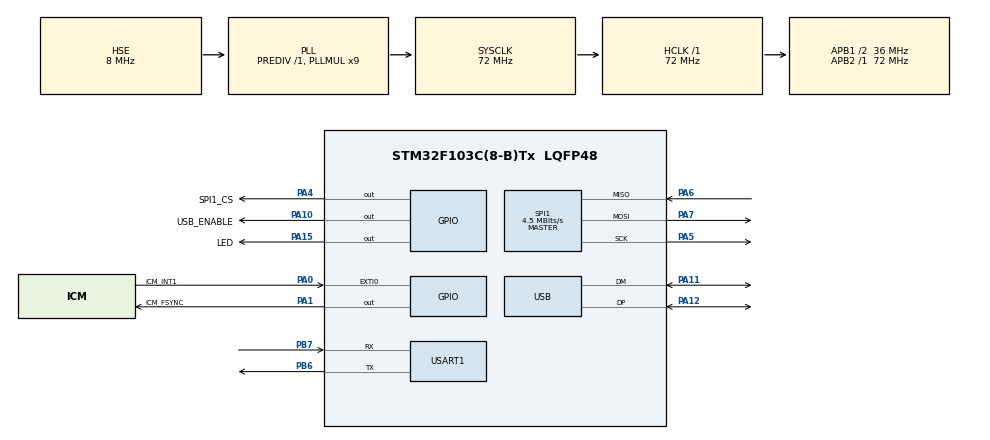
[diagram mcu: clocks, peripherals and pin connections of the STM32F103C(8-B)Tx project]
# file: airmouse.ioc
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Dma.Request0=SPI1_RX
Dma.Request1=SPI1_TX
Dma.Request2=USART1_RX
Dma.Request3=USART1_TX
Dma.SPI1_RX.0.Direction=DMA_PERIPH_TO_MEMORY
Dma.SPI1_RX.0.Instance=DMA1_Channel2
Dma.SPI1_RX.0.MemDataAlignment=DMA_MDATAALIGN_BYTE
Dma.SPI1_RX.0.MemInc=DMA_MINC_ENABLE
Dma.SPI1_RX.0.Mode=DMA_NORMAL
Dma.SPI1_RX.0.PeriphDataAlignment=DMA_PDATAALIGN_BYTE
Dma.SPI1_RX.0.PeriphInc=DMA_PINC_DISABLE
Dma.SPI1_RX.0.Priority=DMA_PRIORITY_LOW
Dma.SPI1_TX.1.Direction=DMA_MEMORY_TO_PERIPH
Dma.SPI1_TX.1.Instance=DMA1_Channel3
Dma.SPI1_TX.1.MemDataAlignment=DMA_MDATAALIGN_BYTE
Dma.SPI1_TX.1.MemInc=DMA_MINC_ENABLE
Dma.SPI1_TX.1.Mode=DMA_NORMAL
Dma.SPI1_TX.1.PeriphDataAlignment=DMA_PDATAALIGN_BYTE
Dma.SPI1_TX.1.PeriphInc=DMA_PINC_DISABLE
Dma.SPI1_TX.1.Priority=DMA_PRIORITY_LOW
Dma.USART1_RX.2.Direction=DMA_PERIPH_TO_MEMORY
Dma.USART1_RX.2.Instance=DMA1_Channel5
Dma.USART1_RX.2.MemDataAlignment=DMA_MDATAALIGN_BYTE
Dma.USART1_RX.2.MemInc=DMA_MINC_ENABLE
Dma.USART1_RX.2.Mode=DMA_NORMAL
Dma.USART1_RX.2.PeriphDataAlignment=DMA_PDATAALIGN_BYTE
Dma.USART1_RX.2.PeriphInc=DMA_PINC_DISABLE
Dma.USART1_RX.2.Priority=DMA_PRIORITY_LOW
Dma.USART1_TX.3.Direction=DMA_MEMORY_TO_PERIPH
Dma.USART1_TX.3.Instance=DMA1_Channel4
Dma.USART1_TX.3.MemDataAlignment=DMA_MDATAALIGN_BYTE
Dma.USART1_TX.3.MemInc=DMA_MINC_ENABLE
Dma.USART1_TX.3.Mode=DMA_NORMAL
Dma.USART1_TX.3.PeriphDataAlignment=DMA_PDATAALIGN_BYTE
Dma.USART1_TX.3.PeriphInc=DMA_PINC_DISABLE
Dma.USART1_TX.3.Priority=DMA_PRIORITY_LOW
FREERTOS.Tasks01=defaultTask,24,128,StartDefaultTask,Default,NULL,Dynamic,NULL,NULL
Mcu.Family=STM32F1
Mcu.Name=STM32F103C(8-B)Tx
Mcu.Package=LQFP48
NVIC.DMA1_Channel2_IRQn=true\:5\:0\:false\:false\:true\:true\:false\:true\:true
NVIC.DMA1_Channel3_IRQn=true\:5\:0\:false\:false\:true\:true\:false\:true\:true
NVIC.DMA1_Channel4_IRQn=true\:5\:0\:false\:false\:true\:true\:false\:true\:true
NVIC.DMA1_Channel5_IRQn=true\:5\:0\:false\:false\:true\:true\:false\:true\:true
NVIC.PriorityGroup=NVIC_PRIORITYGROUP_4
NVIC.TIM4_IRQn=true\:15\:0\:false\:false\:true\:false\:false\:true\:true
NVIC.TimeBase=TIM4_IRQn
NVIC.TimeBaseIP=TIM4
NVIC.USART1_IRQn=true\:5\:0\:false\:false\:true\:true\:true\:true\:true
NVIC.USB_LP_CAN1_RX0_IRQn=true\:5\:0\:false\:false\:true\:true\:false\:true\:true
PA0-WKUP.GPIO_Label=ICM_INT1
PA0-WKUP.GPIO_ModeDefaultEXTI=GPIO_MODE_IT_RISING
PA0-WKUP.GPIO_PuPd=GPIO_PULLUP
PA0-WKUP.Signal=GPXTI0
PA1.GPIO_Label=ICM_FSYNC
PA1.Signal=GPIO_Output
PA10.GPIO_Label=USB_ENABLE
PA10.Signal=GPIO_Output
PA11.Mode=Device
PA11.Signal=USB_DM
PA12.Mode=Device
PA12.Signal=USB_DP
PA13.Mode=Trace_Asynchronous_SW
PA13.Signal=SYS_JTMS-SWDIO
PA14.Mode=Trace_Asynchronous_SW
PA14.Signal=SYS_JTCK-SWCLK
PA15.GPIO_Label=LED
PA15.Signal=GPIO_Output
PA4.GPIO_Label=SPI1_CS
PA4.Signal=GPIO_Output
PA5.Mode=Full_Duplex_Master
PA5.Signal=SPI1_SCK
PA6.Mode=Full_Duplex_Master
PA6.Signal=SPI1_MISO
PA7.Mode=Full_Duplex_Master
PA7.Signal=SPI1_MOSI
PB3.Mode=Trace_Asynchronous_SW
PB3.Signal=SYS_JTDO-TRACESWO
PB6.Mode=Asynchronous
PB6.Signal=USART1_TX
PB7.Mode=Asynchronous
PB7.Signal=USART1_RX
PD0-OSC_IN.Mode=HSE-External-Oscillator
PD0-OSC_IN.Signal=RCC_OSC_IN
PD1-OSC_OUT.Mode=HSE-External-Oscillator
PD1-OSC_OUT.Signal=RCC_OSC_OUT
ProjectManager.HeapSize=0x200
ProjectManager.StackSize=0x400
ProjectManager.TargetToolchain=CMake
RCC.AHBFreq_Value=72000000
RCC.APB1CLKDivider=RCC_HCLK_DIV2
RCC.APB1Freq_Value=36000000
RCC.APB1TimFreq_Value=72000000
RCC.APB2Freq_Value=72000000
RCC.APB2TimFreq_Value=72000000
RCC.HCLKFreq_Value=72000000
RCC.PLLMUL=RCC_PLL_MUL9
RCC.SYSCLKFreq_VALUE=72000000
RCC.SYSCLKSource=RCC_SYSCLKSOURCE_PLLCLK
RCC.USBFreq_Value=48000000
RCC.USBPrescaler=RCC_USBCLKSOURCE_PLL_DIV1_5
SPI1.BaudRatePrescaler=SPI_BAUDRATEPRESCALER_16
SPI1.CLKPhase=SPI_PHASE_2EDGE
SPI1.CLKPolarity=SPI_POLARITY_HIGH
SPI1.CalculateBaudRate=4.5 MBits/s
SPI1.Direction=SPI_DIRECTION_2LINES
SPI1.Mode=SPI_MODE_MASTER
SPI1.VirtualType=VM_MASTER
USART1.VirtualMode=VM_ASYNC
USB_DEVICE.CLASS_NAME_FS=HID
USB_DEVICE.VirtualMode=Hid
USB_DEVICE.VirtualModeFS=Hid_FS
VP_FREERTOS_VS_CMSIS_V2.Mode=CMSIS_V2
VP_SYS_VS_tim4.Mode=TIM4
VP_USB_DEVICE_VS_USB_DEVICE_HID_FS.Mode=HID_FS
board=custom

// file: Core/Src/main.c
/* USER CODE BEGIN Header */
/**
  ******************************************************************************
  * @file           : main.c
  * @brief          : Main program body
  ******************************************************************************
  * @attention
  *
  * Copyright (c) 2024 STMicroelectronics.
  * All rights reserved.
  *
  * This software is licensed under terms that can be found in the LICENSE file
  * in the root directory of this software component.
  * If no LICENSE file comes with this software, it is provided AS-IS.
  *
  ******************************************************************************
  */
/* USER CODE END Header */
#include "main.h"
#include "cmsis_os.h"
#include "dma.h"
#include "spi.h"
#include "usart.h"
#include "usb_device.h"
#include "gpio.h"

void SystemClock_Config(void);
void MX_FREERTOS_Init(void);

int main(void)
{

  /* MCU Configuration--------------------------------------------------------*/

  /* Reset of all peripherals, Initializes the Flash interface and the Systick. */
  HAL_Init();

  /* Configure the system clock */
  SystemClock_Config();

  /* Initialize all configured peripherals */
  MX_GPIO_Init();
  MX_DMA_Init();
  MX_SPI1_Init();
  MX_USART1_UART_Init();

  /* Init scheduler */
  osKernelInitialize();

  /* Call init function for freertos objects (in cmsis_os2.c) */
  MX_FREERTOS_Init();

  /* Start scheduler */
  osKernelStart();

  /* We should never get here as control is now taken by the scheduler */

  /* Infinite loop */
  while (1)
  {

  }
}

void SystemClock_Config(void)
{
  RCC_OscInitTypeDef RCC_OscInitStruct = {0};
  RCC_ClkInitTypeDef RCC_ClkInitStruct = {0};
  RCC_PeriphCLKInitTypeDef PeriphClkInit = {0};

  /** Initializes the RCC Oscillators according to the specified parameters
  * in the RCC_OscInitTypeDef structure.
  */
  RCC_OscInitStruct.OscillatorType = RCC_OSCILLATORTYPE_HSE;
  RCC_OscInitStruct.HSEState = RCC_HSE_ON;
  RCC_OscInitStruct.HSEPredivValue = RCC_HSE_PREDIV_DIV1;
  RCC_OscInitStruct.HSIState = RCC_HSI_ON;
  RCC_OscInitStruct.PLL.PLLState = RCC_PLL_ON;
  RCC_OscInitStruct.PLL.PLLSource = RCC_PLLSOURCE_HSE;
  RCC_OscInitStruct.PLL.PLLMUL = RCC_PLL_MUL9;
  if (HAL_RCC_OscConfig(&RCC_OscInitStruct) != HAL_OK)
  {
    Error_Handler();
  }

  /** Initializes the CPU, AHB and APB buses clocks
  */
  RCC_ClkInitStruct.ClockType = RCC_CLOCKTYPE_HCLK|RCC_CLOCKTYPE_SYSCLK
                              |RCC_CLOCKTYPE_PCLK1|RCC_CLOCKTYPE_PCLK2;
  RCC_ClkInitStruct.SYSCLKSource = RCC_SYSCLKSOURCE_PLLCLK;
  RCC_ClkInitStruct.AHBCLKDivider = RCC_SYSCLK_DIV1;
  RCC_ClkInitStruct.APB1CLKDivider = RCC_HCLK_DIV2;
  RCC_ClkInitStruct.APB2CLKDivider = RCC_HCLK_DIV1;

  if (HAL_RCC_ClockConfig(&RCC_ClkInitStruct, FLASH_LATENCY_2) != HAL_OK)
  {
    Error_Handler();
  }
  PeriphClkInit.PeriphClockSelection = RCC_PERIPHCLK_USB;
  PeriphClkInit.UsbClockSelection = RCC_USBCLKSOURCE_PLL_DIV1_5;
  if (HAL_RCCEx_PeriphCLKConfig(&PeriphClkInit) != HAL_OK)
  {
    Error_Handler();
  }
}

void HAL_TIM_PeriodElapsedCallback(TIM_HandleTypeDef *htim)
{
  if (htim->Instance == TIM4) {
    HAL_IncTick();
  }
}

void Error_Handler(void)
{
  __disable_irq();
  while (1)
  {
  }
}

#ifdef  USE_FULL_ASSERT
/**
  * @brief  Reports the name of the source file and the source line number
  *         where the assert_param error has occurred.
  * @param  file: pointer to the source file name
  * @param  line: assert_param error line source number
  * @retval None
  */
void assert_failed(uint8_t *file, uint32_t line)
{
  /* USER CODE BEGIN 6 */
  /* User can add his own implementation to report the file name and line number,
     ex: printf("Wrong parameters value: file %s on line %d\r\n", file, line) */
    printf("Wrong parameters value: file %s on line %lu\r\n", file, line);
  /* USER CODE END 6 */
}
#endif /* USE_FULL_ASSERT */

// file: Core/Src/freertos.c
/* USER CODE BEGIN Header */
/**
  ******************************************************************************
  * File Name          : freertos.c
  * Description        : Code for freertos applications
  ******************************************************************************
  * @attention
  *
  * Copyright (c) 2024 STMicroelectronics.
  * All rights reserved.
  *
  * This software is licensed under terms that can be found in the LICENSE file
  * in the root directory of this software component.
  * If no LICENSE file comes with this software, it is provided AS-IS.
  *
  ******************************************************************************
  */
/* USER CODE END Header */

#include "FreeRTOS.h"
#include "task.h"
#include "main.h"
#include "cmsis_os.h"

/* Definitions for defaultTask */
osThreadId_t defaultTaskHandle;
const osThreadAttr_t defaultTask_attributes = {
  .name = "defaultTask",
  .stack_size = 128 * 4,
  .priority = (osPriority_t) osPriorityNormal,
};

void StartDefaultTask(void *argument);

extern void MX_USB_DEVICE_Init(void);
void MX_FREERTOS_Init(void); /* (MISRA C 2004 rule 8.1) */

void MX_FREERTOS_Init(void) {

  /* Create the thread(s) */
  /* creation of defaultTask */
  defaultTaskHandle = osThreadNew(StartDefaultTask, NULL, &defaultTask_attributes);

  /* USER CODE BEGIN RTOS_THREADS */
  /* add threads, ... */

  userShellInit();
  /* USER CODE END RTOS_THREADS */

}

void StartDefaultTask(void *argument)
{
  /* init code for USB_DEVICE */
  MX_USB_DEVICE_Init();
  /* USER CODE BEGIN StartDefaultTask */

  /** Enable USB */
  HAL_GPIO_WritePin(USB_ENABLE_GPIO_Port, USB_ENABLE_Pin, GPIO_PIN_SET);

  NineAxisSensorInit();
  /* Infinite loop */
  for(;;)
  {
    osDelay(1000);
    HAL_GPIO_TogglePin(LED_GPIO_Port, LED_Pin);
  }
  /* USER CODE END StartDefaultTask */
}
